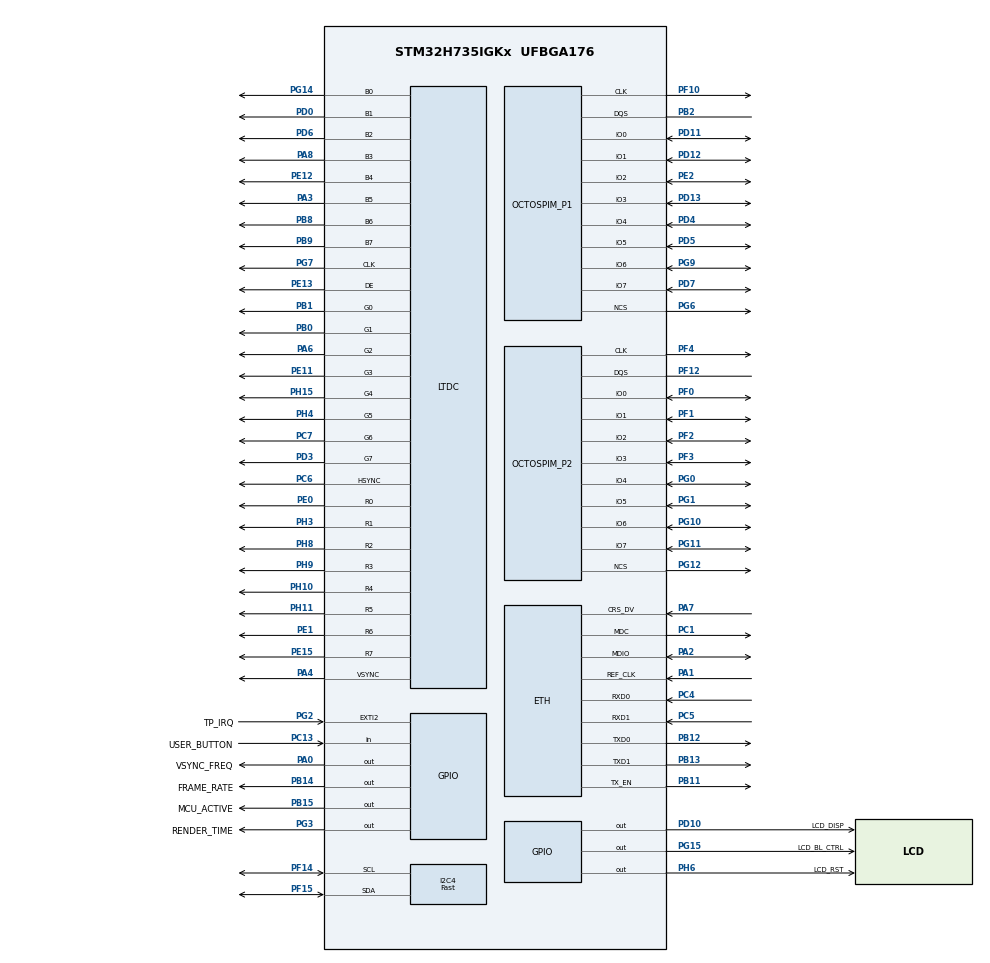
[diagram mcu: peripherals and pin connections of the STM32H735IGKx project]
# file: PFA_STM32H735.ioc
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CORTEX_M7.AccessPermission-Cortex_Memory_Protection_Unit_Region0_Settings=MPU_REGION_FULL_ACCESS
CORTEX_M7.AccessPermission-Cortex_Memory_Protection_Unit_Region2_Settings=MPU_REGION_FULL_ACCESS
CORTEX_M7.AccessPermission-Cortex_Memory_Protection_Unit_Region4_Settings=MPU_REGION_FULL_ACCESS
CORTEX_M7.BaseAddress-Cortex_Memory_Protection_Unit_Region0_Settings=0x24000000
CORTEX_M7.BaseAddress-Cortex_Memory_Protection_Unit_Region1_Settings=0x70000000
CORTEX_M7.BaseAddress-Cortex_Memory_Protection_Unit_Region2_Settings=0x70000000
CORTEX_M7.BaseAddress-Cortex_Memory_Protection_Unit_Region3_Settings=0x90000000
CORTEX_M7.BaseAddress-Cortex_Memory_Protection_Unit_Region4_Settings=0x90000000
CORTEX_M7.CPU_DCache=Enabled
CORTEX_M7.CPU_ICache=Enabled
CORTEX_M7.DisableExec-Cortex_Memory_Protection_Unit_Region0_Settings=MPU_INSTRUCTION_ACCESS_DISABLE
CORTEX_M7.DisableExec-Cortex_Memory_Protection_Unit_Region1_Settings=MPU_INSTRUCTION_ACCESS_DISABLE
CORTEX_M7.DisableExec-Cortex_Memory_Protection_Unit_Region2_Settings=MPU_INSTRUCTION_ACCESS_DISABLE
CORTEX_M7.DisableExec-Cortex_Memory_Protection_Unit_Region3_Settings=MPU_INSTRUCTION_ACCESS_DISABLE
CORTEX_M7.DisableExec-Cortex_Memory_Protection_Unit_Region4_Settings=MPU_INSTRUCTION_ACCESS_DISABLE
CORTEX_M7.Enable-Cortex_Memory_Protection_Unit_Region0_Settings=MPU_REGION_ENABLE
CORTEX_M7.Enable-Cortex_Memory_Protection_Unit_Region1_Settings=MPU_REGION_ENABLE
CORTEX_M7.Enable-Cortex_Memory_Protection_Unit_Region2_Settings=MPU_REGION_ENABLE
CORTEX_M7.Enable-Cortex_Memory_Protection_Unit_Region3_Settings=MPU_REGION_ENABLE
CORTEX_M7.Enable-Cortex_Memory_Protection_Unit_Region4_Settings=MPU_REGION_ENABLE
CORTEX_M7.IsBufferable-Cortex_Memory_Protection_Unit_Region0_Settings=MPU_ACCESS_BUFFERABLE
CORTEX_M7.IsBufferable-Cortex_Memory_Protection_Unit_Region2_Settings=MPU_ACCESS_BUFFERABLE
CORTEX_M7.IsCacheable-Cortex_Memory_Protection_Unit_Region0_Settings=MPU_ACCESS_CACHEABLE
CORTEX_M7.IsCacheable-Cortex_Memory_Protection_Unit_Region2_Settings=MPU_ACCESS_CACHEABLE
CORTEX_M7.IsCacheable-Cortex_Memory_Protection_Unit_Region4_Settings=MPU_ACCESS_CACHEABLE
CORTEX_M7.MPU_Control=MPU_PRIVILEGED_DEFAULT
CORTEX_M7.Size-Cortex_Memory_Protection_Unit_Region0_Settings=MPU_REGION_SIZE_512KB
CORTEX_M7.Size-Cortex_Memory_Protection_Unit_Region1_Settings=MPU_REGION_SIZE_512MB
CORTEX_M7.Size-Cortex_Memory_Protection_Unit_Region2_Settings=MPU_REGION_SIZE_8MB
CORTEX_M7.Size-Cortex_Memory_Protection_Unit_Region3_Settings=MPU_REGION_SIZE_512MB
CORTEX_M7.Size-Cortex_Memory_Protection_Unit_Region4_Settings=MPU_REGION_SIZE_64MB
CORTEX_M7.TypeExtField-Cortex_Memory_Protection_Unit_Region0_Settings=MPU_TEX_LEVEL1
DMA2D.ColorMode=DMA2D_OUTPUT_RGB888
DMA2D.Mode=DMA2D_R2M
ETH.MediaInterface=HAL_ETH_RMII_MODE
FREERTOS.Tasks01=defaultTask,24,2048,StartDefaultTask,Default,NULL,Dynamic,NULL,NULL;TouchGFXTask,24,2048,TouchGFX_Task,As external,NULL,Dynamic,NULL,NULL;videoTask,8,1024,videoTaskFunc,As external,NULL,Dynamic,NULL,NULL
FREERTOS.configTOTAL_HEAP_SIZE=75000
FREERTOS.configUSE_APPLICATION_TASK_TAG=1
FREERTOS.configUSE_IDLE_HOOK=1
I2C4.I2C_Speed_Mode=I2C_Fast
I2C4.Timing=0x00D049FB
LIBJPEG.RGB_ORDERING=BGR
LTDC.ActiveH=272
LTDC.ActiveW=480
LTDC.Alpha_L0=255
LTDC.FBStartAdress_L0=0x70000000
LTDC.FBStartAdress_L1=0x70000000
LTDC.HBP=13
LTDC.HFP=32
LTDC.HSync=41
LTDC.ImageHeight_L0=272
LTDC.ImageWidth_L0=480
LTDC.Layers=0
LTDC.PixelFormat_L0=LTDC_PIXEL_FORMAT_RGB888
LTDC.VSync=10
LTDC.WindowX1_L0=480
LTDC.WindowY1_L0=272
LWIP.BSP.number=1
LWIP.GATEWAY_ADDRESS=192.168.000.001
LWIP.IP_ADDRESS=192.168.000.020
LWIP.LWIP_DHCP=0
LWIP.LWIP_IPV6=1
LWIP.NETMASK_ADDRESS=255.255.255.000
LWIP.Version=v2.2.1_Cube
LWIP0.BSP.STBoard=false
LWIP0.BSP.api=BSP_COMPONENT_DRIVER
LWIP0.BSP.component=LAN8742
LWIP0.BSP.instance=LAN8742
LWIP0.BSP.name=Driver_PHY
LWIP0.BSP.semaphore=S_LAN8742
LWIP0.BSP.solution=LAN8742
Mcu.Family=STM32H7
Mcu.Name=STM32H735IGKx
Mcu.Package=UFBGA176
NVIC.DMA2D_IRQn=true\:5\:0\:true\:false\:true\:false\:true\:true\:true
NVIC.ETH_IRQn=true\:5\:0\:false\:false\:true\:true\:true\:true\:true
NVIC.EXTI2_IRQn=true\:5\:0\:false\:false\:true\:true\:true\:true\:true
NVIC.LTDC_IRQn=true\:5\:0\:true\:false\:true\:false\:true\:true\:true
NVIC.PriorityGroup=NVIC_PRIORITYGROUP_4
NVIC.TIM6_DAC_IRQn=true\:0\:0\:false\:false\:true\:false\:false\:true\:true
NVIC.TimeBase=TIM6_DAC_IRQn
NVIC.TimeBaseIP=TIM6
OCTOSPI1.ChipSelectBoundary=0
OCTOSPI1.ChipSelectHighTime=2
OCTOSPI1.ClockPrescaler=2
OCTOSPI1.FifoThreshold=4
OCTOSPI1.MemoryType=HAL_OSPI_MEMTYPE_MACRONIX
OCTOSPI2.AccessTime=6
OCTOSPI2.ChipSelectBoundary=23
OCTOSPI2.ChipSelectHighTime=4
OCTOSPI2.ClkChipSelectHighTime=0
OCTOSPI2.ClockPrescaler=2
OCTOSPI2.DelayBlockBypass=HAL_OSPI_DELAY_BLOCK_USED
OCTOSPI2.DelayHoldQuarterCycle=HAL_OSPI_DHQC_ENABLE
OCTOSPI2.DeviceSize=24
OCTOSPI2.FifoThreshold=4
OCTOSPI2.LatencyMode=HAL_OSPI_FIXED_LATENCY
OCTOSPI2.RWRecoveryTime=3
OCTOSPI2.Refresh=400
OCTOSPI2.WriteZeroLatency=HAL_OSPI_LATENCY_ON_WRITE
PA0.GPIO_Label=VSYNC_FREQ
PA0.GPIO_Speed=GPIO_SPEED_FREQ_VERY_HIGH
PA0.Signal=GPIO_Output
PA1.Mode=RMII
PA1.Signal=ETH_REF_CLK
PA2.Mode=RMII
PA2.Signal=ETH_MDIO
PA3.GPIO_Speed=GPIO_SPEED_FREQ_VERY_HIGH
PA3.Mode=RGB888
PA3.Signal=LTDC_B5
PA4.GPIO_Speed=GPIO_SPEED_FREQ_VERY_HIGH
PA4.Mode=RGB888
PA4.Signal=LTDC_VSYNC
PA6.GPIO_Speed=GPIO_SPEED_FREQ_VERY_HIGH
PA6.Mode=RGB888
PA6.Signal=LTDC_G2
PA7.Mode=RMII
PA7.Signal=ETH_CRS_DV
PA8.GPIO_Speed=GPIO_SPEED_FREQ_VERY_HIGH
PA8.Mode=RGB888
PA8.Signal=LTDC_B3
PB0.GPIO_Speed=GPIO_SPEED_FREQ_VERY_HIGH
PB0.Mode=RGB888
PB0.Signal=LTDC_G1
PB1.GPIO_Speed=GPIO_SPEED_FREQ_VERY_HIGH
PB1.Mode=RGB888
PB1.Signal=LTDC_G0
PB10.Signal=ETH_RX_ER
PB11.Mode=RMII
PB11.Signal=ETH_TX_EN
PB12.Mode=RMII
PB12.Signal=ETH_TXD0
PB13.Mode=RMII
PB13.Signal=ETH_TXD1
PB14.GPIO_Label=FRAME_RATE
PB14.GPIO_Speed=GPIO_SPEED_FREQ_VERY_HIGH
PB14.Signal=GPIO_Output
PB15.GPIO_Label=MCU_ACTIVE
PB15.GPIO_Speed=GPIO_SPEED_FREQ_VERY_HIGH
PB15.Signal=GPIO_Output
PB2.Mode=OCTOSPI1_Port1_DQS
PB2.Signal=OCTOSPIM_P1_DQS
PB8.GPIO_Speed=GPIO_SPEED_FREQ_VERY_HIGH
PB8.Mode=RGB888
PB8.Signal=LTDC_B6
PB9.GPIO_Speed=GPIO_SPEED_FREQ_VERY_HIGH
PB9.Mode=RGB888
PB9.Signal=LTDC_B7
PC1.Mode=RMII
PC1.Signal=ETH_MDC
PC13.GPIO_Label=USER_BUTTON
PC13.Signal=GPIO_Input
PC4.Mode=RMII
PC4.Signal=ETH_RXD0
PC5.Mode=RMII
PC5.Signal=ETH_RXD1
PC6.GPIO_Speed=GPIO_SPEED_FREQ_VERY_HIGH
PC6.Mode=RGB888
PC6.Signal=LTDC_HSYNC
PC7.GPIO_Speed=GPIO_SPEED_FREQ_VERY_HIGH
PC7.Mode=RGB888
PC7.Signal=LTDC_G6
PD0.GPIO_Speed=GPIO_SPEED_FREQ_VERY_HIGH
PD0.Mode=RGB888
PD0.Signal=LTDC_B1
PD10.GPIO_Label=LCD_DISP
PD10.GPIO_PuPd=GPIO_NOPULL
PD10.GPIO_Speed=GPIO_SPEED_FREQ_LOW
PD10.PinState=GPIO_PIN_RESET
PD10.Signal=GPIO_Output
PD11.Mode=OCTOSPI1_IOL_Port1L
PD11.Signal=OCTOSPIM_P1_IO0
PD12.Mode=OCTOSPI1_IOL_Port1L
PD12.Signal=OCTOSPIM_P1_IO1
PD13.Mode=OCTOSPI1_IOL_Port1L
PD13.Signal=OCTOSPIM_P1_IO3
PD3.GPIO_Speed=GPIO_SPEED_FREQ_VERY_HIGH
PD3.Mode=RGB888
PD3.Signal=LTDC_G7
PD4.Mode=OCTOSPI1_IOH_Port1H
PD4.Signal=OCTOSPIM_P1_IO4
PD5.Mode=OCTOSPI1_IOH_Port1H
PD5.Signal=OCTOSPIM_P1_IO5
PD6.GPIO_Speed=GPIO_SPEED_FREQ_VERY_HIGH
PD6.Mode=RGB888
PD6.Signal=LTDC_B2
PD7.Mode=OCTOSPI1_IOH_Port1H
PD7.Signal=OCTOSPIM_P1_IO7
PE0.GPIO_Speed=GPIO_SPEED_FREQ_VERY_HIGH
PE0.Mode=RGB888
PE0.Signal=LTDC_R0
PE1.GPIO_Speed=GPIO_SPEED_FREQ_VERY_HIGH
PE1.Mode=RGB888
PE1.Signal=LTDC_R6
PE11.GPIO_Speed=GPIO_SPEED_FREQ_VERY_HIGH
PE11.Mode=RGB888
PE11.Signal=LTDC_G3
PE12.GPIO_Speed=GPIO_SPEED_FREQ_VERY_HIGH
PE12.Mode=RGB888
PE12.Signal=LTDC_B4
PE13.GPIO_Speed=GPIO_SPEED_FREQ_VERY_HIGH
PE13.Mode=RGB888
PE13.Signal=LTDC_DE
PE15.GPIO_Speed=GPIO_SPEED_FREQ_VERY_HIGH
PE15.Mode=RGB888
PE15.Signal=LTDC_R7
PE2.Mode=OCTOSPI1_IOL_Port1L
PE2.Signal=OCTOSPIM_P1_IO2
PF0.Mode=OCTOSPI2_IOL_Port2L
PF0.Signal=OCTOSPIM_P2_IO0
PF1.Mode=OCTOSPI2_IOL_Port2L
PF1.Signal=OCTOSPIM_P2_IO1
PF10.Mode=O1_P1_CLK
PF10.Signal=OCTOSPIM_P1_CLK
PF12.Mode=OCTOSPI2_Port2_DQS
PF12.Signal=OCTOSPIM_P2_DQS
PF14.Mode=I2C
PF14.Signal=I2C4_SCL
PF15.Mode=I2C
PF15.Signal=I2C4_SDA
PF2.Mode=OCTOSPI2_IOL_Port2L
PF2.Signal=OCTOSPIM_P2_IO2
PF3.Mode=OCTOSPI2_IOL_Port2L
PF3.Signal=OCTOSPIM_P2_IO3
PF4.Mode=O2_P2_CLK
PF4.Signal=OCTOSPIM_P2_CLK
PG0.Mode=OCTOSPI2_IOH_Port2H
PG0.Signal=OCTOSPIM_P2_IO4
PG1.Mode=OCTOSPI2_IOH_Port2H
PG1.Signal=OCTOSPIM_P2_IO5
PG10.Mode=OCTOSPI2_IOH_Port2H
PG10.Signal=OCTOSPIM_P2_IO6
PG11.Mode=OCTOSPI2_IOH_Port2H
PG11.Signal=OCTOSPIM_P2_IO7
PG12.Mode=OCTOSPI2_Port2_NCS
PG12.Signal=OCTOSPIM_P2_NCS
PG14.GPIO_Speed=GPIO_SPEED_FREQ_VERY_HIGH
PG14.Mode=RGB888
PG14.Signal=LTDC_B0
PG15.GPIO_Label=LCD_BL_CTRL
PG15.Signal=GPIO_Output
PG2.GPIO_Label=TP_IRQ
PG2.GPIO_ModeDefaultEXTI=GPIO_MODE_IT_FALLING
PG2.GPIO_PuPd=GPIO_PULLDOWN
PG2.Signal=GPXTI2
PG3.GPIO_Label=RENDER_TIME
PG3.GPIO_Speed=GPIO_SPEED_FREQ_VERY_HIGH
PG3.Signal=GPIO_Output
PG6.Mode=OCTOSPI1_Port1_NCS
PG6.Signal=OCTOSPIM_P1_NCS
PG7.GPIO_Speed=GPIO_SPEED_FREQ_VERY_HIGH
PG7.Mode=RGB888
PG7.Signal=LTDC_CLK
PG9.Mode=OCTOSPI1_IOH_Port1H
PG9.Signal=OCTOSPIM_P1_IO6
PH0-OSC_IN.Mode=HSE-External-Oscillator
PH0-OSC_IN.Signal=RCC_OSC_IN
PH1-OSC_OUT.Mode=HSE-External-Oscillator
PH1-OSC_OUT.Signal=RCC_OSC_OUT
PH10.GPIO_Speed=GPIO_SPEED_FREQ_VERY_HIGH
PH10.Mode=RGB888
PH10.Signal=LTDC_R4
PH11.GPIO_Speed=GPIO_SPEED_FREQ_VERY_HIGH
PH11.Mode=RGB888
PH11.Signal=LTDC_R5
PH15.GPIO_Speed=GPIO_SPEED_FREQ_VERY_HIGH
PH15.Mode=RGB888
PH15.Signal=LTDC_G4
PH3.GPIO_Speed=GPIO_SPEED_FREQ_VERY_HIGH
PH3.Mode=RGB888
PH3.Signal=LTDC_R1
PH4.GPIO_Speed=GPIO_SPEED_FREQ_VERY_HIGH
PH4.Mode=RGB888
PH4.Signal=LTDC_G5
PH6.GPIO_Label=LCD_RST
PH6.Signal=GPIO_Output
PH8.GPIO_Speed=GPIO_SPEED_FREQ_VERY_HIGH
PH8.Mode=RGB888
PH8.Signal=LTDC_R2
PH9.GPIO_Speed=GPIO_SPEED_FREQ_VERY_HIGH
PH9.Mode=RGB888
PH9.Signal=LTDC_R3
ProjectManager.HeapSize=0x1000
ProjectManager.StackSize=0x1000
ProjectManager.TargetToolchain=STM32CubeIDE
RCC.ADCFreq_Value=200000000
RCC.APB1Freq_Value=137500000
RCC.APB2Freq_Value=137500000
RCC.APB3Freq_Value=137500000
RCC.APB4Freq_Value=137500000
RCC.CortexFreq_Value=550000000
RCC.D1PPRE=RCC_APB3_DIV2
RCC.D2PPRE1=RCC_APB1_DIV2
RCC.D2PPRE2=RCC_APB2_DIV2
RCC.D3PPRE=RCC_APB4_DIV2
RCC.DIVM1=2
RCC.DIVM2=5
RCC.DIVM3=25
RCC.DIVN1=44
RCC.DIVN2=80
RCC.DIVN3=288
RCC.DIVP1=1
RCC.DIVR3=30
RCC.HCLKFreq_Value=275000000
RCC.HPRE=RCC_HCLK_DIV2
RCC.PLL2FRACN=0
RCC.PLL3FRACN=0
RCC.PLLFRACN=0
RCC.PLLSourceVirtual=RCC_PLLSOURCE_HSE
RCC.QSPICLockSelection=RCC_OSPICLKSOURCE_PLL2
RCC.SYSCLKFreq_VALUE=550000000
RCC.SYSCLKSource=RCC_SYSCLKSOURCE_PLLCLK
RCC.SupplySource=PWR_DIRECT_SMPS_SUPPLY
RCC.USBFreq_Value=275000000
STMicroelectronics.X-CUBE-TOUCHGFX.4.26.1.ApplicationCcGraphicsJjApplication=TouchGFXOoGenerator
STMicroelectronics.X-CUBE-TOUCHGFX.4.26.1.tgfx_address1=0x70000000
STMicroelectronics.X-CUBE-TOUCHGFX.4.26.1.tgfx_address2=0x70060000
STMicroelectronics.X-CUBE-TOUCHGFX.4.26.1.tgfx_buffering_strategy=Double
STMicroelectronics.X-CUBE-TOUCHGFX.4.26.1.tgfx_display_interface=disp_ltdc
STMicroelectronics.X-CUBE-TOUCHGFX.4.26.1.tgfx_hardware_accelerator=dma_2d
STMicroelectronics.X-CUBE-TOUCHGFX.4.26.1.tgfx_location=Allocate
STMicroelectronics.X-CUBE-TOUCHGFX.4.26.1.tgfx_vector_fonts=Enabled
STMicroelectronics.X-CUBE-TOUCHGFX.4.26.1.tgfx_vector_rendering=Software
STMicroelectronics.X-CUBE-TOUCHGFX.4.26.1.tgfx_video=Software
STMicroelectronics.X-CUBE-TOUCHGFX.4.26.1.tgfx_video_buffer_format=RGB888\:3
STMicroelectronics.X-CUBE-TOUCHGFX.4.26.1.tgfx_video_height=272
STMicroelectronics.X-CUBE-TOUCHGFX.4.26.1.tgfx_video_strategy=1
STMicroelectronics.X-CUBE-TOUCHGFX.4.26.1.tgfx_video_width=480
STMicroelectronics.X-CUBE-TOUCHGFX.4.26.1.tgfx_vsync=vsync_ltdc
VP_CRC_VS_CRC.Mode=CRC_Activate
VP_DMA2D_VS_DMA2D.Mode=DMA2D_Activate
VP_FREERTOS_VS_CMSIS_V2.Mode=CMSIS_V2
VP_LIBJPEG_VS_JPEGLIB.Mode=Enabled
VP_LWIP_VS_Enabled.Mode=Enabled
VP_MEMORYMAP_VS_MEMORYMAP.Mode=CurAppReg
VP_OCTOSPI1_VS_octo.Mode=octo_mode
VP_OCTOSPI2_VS_octo.Mode=hyperbus_mode
VP_STMicroelectronics.X-CUBE-TOUCHGFX_VS_GraphicsJjApplication_4.26.1.Mode=GraphicsJjApplication
VP_SYS_VS_tim6.Mode=TIM6
board=custom

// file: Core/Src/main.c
/* USER CODE BEGIN Header */
/**
  ******************************************************************************
  * @file           : main.c
  * @brief          : Main program body
  ******************************************************************************
  * @attention
  *
  * <h2><center>&copy; Copyright (c) 2020 STMicroelectronics.
  * All rights reserved.</center></h2>
  *
  * This software component is licensed by ST under Ultimate Liberty license
  * SLA0044, the "License"; You may not use this file except in compliance with
  * the License. You may obtain a copy of the License at:
  *                             www.st.com/SLA0044
  *
  ******************************************************************************
  */
/* USER CODE END Header */
#include "main.h"
#include "FreeRTOS.h"
#include "cmsis_os2.h"
#include "libjpeg.h"
#include "lwip.h"
#include "app_touchgfx.h"

/* USER CODE BEGIN Includes */
#include "task.h"
#include "stm32h735g_discovery_ospi.h"
#include "stm32h7xx_hal_ospi.h"
/* USER CODE END Includes */

CRC_HandleTypeDef hcrc;

DMA2D_HandleTypeDef hdma2d;

I2C_HandleTypeDef hi2c4;

LTDC_HandleTypeDef hltdc;

OSPI_HandleTypeDef hospi1;
OSPI_HandleTypeDef hospi2;

/* Definitions for defaultTask */
osThreadId_t defaultTaskHandle;
const osThreadAttr_t defaultTask_attributes = {
  .name = "defaultTask",
  .stack_size = 2048 * 4,
  .priority = (osPriority_t) osPriorityNormal,
};
/* Definitions for TouchGFXTask */
osThreadId_t TouchGFXTaskHandle;
const osThreadAttr_t TouchGFXTask_attributes = {
  .name = "TouchGFXTask",
  .stack_size = 2048 * 4,
  .priority = (osPriority_t) osPriorityNormal,
};
/* Definitions for videoTask */
osThreadId_t videoTaskHandle;
const osThreadAttr_t videoTask_attributes = {
  .name = "videoTask",
  .stack_size = 1024 * 4,
  .priority = (osPriority_t) osPriorityLow,
};

void SystemClock_Config(void);
void PeriphCommonClock_Config(void);
static void MPU_Config(void);
static void MX_GPIO_Init(void);
static void MX_CRC_Init(void);
static void MX_DMA2D_Init(void);
static void MX_LTDC_Init(void);
static void MX_OCTOSPI1_Init(void);
static void MX_OCTOSPI2_Init(void);
static void MX_I2C4_Init(void);
void StartDefaultTask(void *argument);
extern void TouchGFX_Task(void *argument);
extern void videoTaskFunc(void *argument);

int main(void)
{

  /* MPU Configuration--------------------------------------------------------*/
  MPU_Config();

  /* Enable the CPU Cache */

  /* Enable I-Cache---------------------------------------------------------*/
  SCB_EnableICache();

  /* Enable D-Cache---------------------------------------------------------*/
  SCB_EnableDCache();

  /* MCU Configuration--------------------------------------------------------*/

  /* Reset of all peripherals, Initializes the Flash interface and the Systick. */
  HAL_Init();

  /* USER CODE BEGIN Init */

  {
    MPU_Region_InitTypeDef MPU_InitStruct = {0};
    HAL_MPU_Disable();
    MPU_InitStruct.Enable = MPU_REGION_ENABLE;
    MPU_InitStruct.Number = MPU_REGION_NUMBER0;
    MPU_InitStruct.BaseAddress = 0x24000000;
    MPU_InitStruct.Size = MPU_REGION_SIZE_512KB;
    MPU_InitStruct.SubRegionDisable = 0x0;
    MPU_InitStruct.TypeExtField = MPU_TEX_LEVEL1;
    MPU_InitStruct.AccessPermission = MPU_REGION_FULL_ACCESS;
    MPU_InitStruct.DisableExec = MPU_INSTRUCTION_ACCESS_DISABLE;
    MPU_InitStruct.IsShareable = MPU_ACCESS_NOT_SHAREABLE;
    MPU_InitStruct.IsCacheable = MPU_ACCESS_CACHEABLE;
    MPU_InitStruct.IsBufferable = MPU_ACCESS_BUFFERABLE;
    HAL_MPU_ConfigRegion(&MPU_InitStruct);

    /* Ethernet DMA Descriptors at 0x30000000 (Non-cacheable) */
    MPU_InitStruct.Number = MPU_REGION_NUMBER5;
    MPU_InitStruct.BaseAddress = 0x30000000;
    MPU_InitStruct.Size = MPU_REGION_SIZE_256B;
    MPU_InitStruct.TypeExtField = MPU_TEX_LEVEL0;
    MPU_InitStruct.IsShareable = MPU_ACCESS_SHAREABLE;
    MPU_InitStruct.IsCacheable = MPU_ACCESS_NOT_CACHEABLE;
    MPU_InitStruct.IsBufferable = MPU_ACCESS_NOT_BUFFERABLE;
    HAL_MPU_ConfigRegion(&MPU_InitStruct);

    HAL_MPU_Enable(MPU_PRIVILEGED_DEFAULT);
  }

  /* USER CODE END Init */

  /* Configure the system clock */
  SystemClock_Config();

  /* Configure the peripherals common clocks */
  PeriphCommonClock_Config();

  /* Initialize all configured peripherals */
  MX_GPIO_Init();
  MX_CRC_Init();
  MX_DMA2D_Init();
  MX_LTDC_Init();
  MX_OCTOSPI1_Init();
  MX_OCTOSPI2_Init();
  MX_LIBJPEG_Init();
  MX_I2C4_Init();
  MX_TouchGFX_Init();
  /* Call PreOsInit function */
  MX_TouchGFX_PreOSInit();

  /* Init scheduler */
  osKernelInitialize();

  /* Create the thread(s) */
  /* creation of defaultTask */
  defaultTaskHandle = osThreadNew(StartDefaultTask, NULL, &defaultTask_attributes);

  /* creation of TouchGFXTask */
  TouchGFXTaskHandle = osThreadNew(TouchGFX_Task, NULL, &TouchGFXTask_attributes);

  /* creation of videoTask */
  videoTaskHandle = osThreadNew(videoTaskFunc, NULL, &videoTask_attributes);

  /* Start scheduler */
  osKernelStart();

  /* We should never get here as control is now taken by the scheduler */

  /* Infinite loop */
  while (1)
  {

  }
}

void SystemClock_Config(void)
{
  RCC_OscInitTypeDef RCC_OscInitStruct = {0};
  RCC_ClkInitTypeDef RCC_ClkInitStruct = {0};

  /** Supply configuration update enable
  */
  HAL_PWREx_ConfigSupply(PWR_DIRECT_SMPS_SUPPLY);

  /** Configure the main internal regulator output voltage
  */
  __HAL_PWR_VOLTAGESCALING_CONFIG(PWR_REGULATOR_VOLTAGE_SCALE0);

  while(!__HAL_PWR_GET_FLAG(PWR_FLAG_VOSRDY)) {}

  /** Initializes the RCC Oscillators according to the specified parameters
  * in the RCC_OscInitTypeDef structure.
  */
  RCC_OscInitStruct.OscillatorType = RCC_OSCILLATORTYPE_HSE;
  RCC_OscInitStruct.HSEState = RCC_HSE_ON;
  RCC_OscInitStruct.PLL.PLLState = RCC_PLL_ON;
  RCC_OscInitStruct.PLL.PLLSource = RCC_PLLSOURCE_HSE;
  RCC_OscInitStruct.PLL.PLLM = 2;
  RCC_OscInitStruct.PLL.PLLN = 44;
  RCC_OscInitStruct.PLL.PLLP = 1;
  RCC_OscInitStruct.PLL.PLLQ = 2;
  RCC_OscInitStruct.PLL.PLLR = 2;
  RCC_OscInitStruct.PLL.PLLRGE = RCC_PLL1VCIRANGE_3;
  RCC_OscInitStruct.PLL.PLLVCOSEL = RCC_PLL1VCOWIDE;
  RCC_OscInitStruct.PLL.PLLFRACN = 0;
  if (HAL_RCC_OscConfig(&RCC_OscInitStruct) != HAL_OK)
  {
    Error_Handler();
  }

  /** Initializes the CPU, AHB and APB buses clocks
  */
  RCC_ClkInitStruct.ClockType = RCC_CLOCKTYPE_HCLK|RCC_CLOCKTYPE_SYSCLK
                              |RCC_CLOCKTYPE_PCLK1|RCC_CLOCKTYPE_PCLK2
                              |RCC_CLOCKTYPE_D3PCLK1|RCC_CLOCKTYPE_D1PCLK1;
  RCC_ClkInitStruct.SYSCLKSource = RCC_SYSCLKSOURCE_PLLCLK;
  RCC_ClkInitStruct.SYSCLKDivider = RCC_SYSCLK_DIV1;
  RCC_ClkInitStruct.AHBCLKDivider = RCC_HCLK_DIV2;
  RCC_ClkInitStruct.APB3CLKDivider = RCC_APB3_DIV2;
  RCC_ClkInitStruct.APB1CLKDivider = RCC_APB1_DIV2;
  RCC_ClkInitStruct.APB2CLKDivider = RCC_APB2_DIV2;
  RCC_ClkInitStruct.APB4CLKDivider = RCC_APB4_DIV2;

  if (HAL_RCC_ClockConfig(&RCC_ClkInitStruct, FLASH_LATENCY_3) != HAL_OK)
  {
    Error_Handler();
  }
}

void PeriphCommonClock_Config(void)
{
  RCC_PeriphCLKInitTypeDef PeriphClkInitStruct = {0};

  /** Initializes the peripherals clock
  */
  PeriphClkInitStruct.PeriphClockSelection = RCC_PERIPHCLK_OSPI;
  PeriphClkInitStruct.PLL2.PLL2M = 5;
  PeriphClkInitStruct.PLL2.PLL2N = 80;
  PeriphClkInitStruct.PLL2.PLL2P = 2;
  PeriphClkInitStruct.PLL2.PLL2Q = 2;
  PeriphClkInitStruct.PLL2.PLL2R = 2;
  PeriphClkInitStruct.PLL2.PLL2RGE = RCC_PLL2VCIRANGE_2;
  PeriphClkInitStruct.PLL2.PLL2VCOSEL = RCC_PLL2VCOWIDE;
  PeriphClkInitStruct.PLL2.PLL2FRACN = 0;
  PeriphClkInitStruct.OspiClockSelection = RCC_OSPICLKSOURCE_PLL2;
  if (HAL_RCCEx_PeriphCLKConfig(&PeriphClkInitStruct) != HAL_OK)
  {
    Error_Handler();
  }
}

static void MX_CRC_Init(void)
{

  hcrc.Instance = CRC;
  hcrc.Init.DefaultPolynomialUse = DEFAULT_POLYNOMIAL_ENABLE;
  hcrc.Init.DefaultInitValueUse = DEFAULT_INIT_VALUE_ENABLE;
  hcrc.Init.InputDataInversionMode = CRC_INPUTDATA_INVERSION_NONE;
  hcrc.Init.OutputDataInversionMode = CRC_OUTPUTDATA_INVERSION_DISABLE;
  hcrc.InputDataFormat = CRC_INPUTDATA_FORMAT_BYTES;
  if (HAL_CRC_Init(&hcrc) != HAL_OK)
  {
    Error_Handler();
  }

}

static void MX_DMA2D_Init(void)
{

  hdma2d.Instance = DMA2D;
  hdma2d.Init.Mode = DMA2D_R2M;
  hdma2d.Init.ColorMode = DMA2D_OUTPUT_RGB888;
  hdma2d.Init.OutputOffset = 0;
  if (HAL_DMA2D_Init(&hdma2d) != HAL_OK)
  {
    Error_Handler();
  }

}

static void MX_I2C4_Init(void)
{

  hi2c4.Instance = I2C4;
  hi2c4.Init.Timing = 0x00D049FB;
  hi2c4.Init.OwnAddress1 = 0;
  hi2c4.Init.AddressingMode = I2C_ADDRESSINGMODE_7BIT;
  hi2c4.Init.DualAddressMode = I2C_DUALADDRESS_DISABLE;
  hi2c4.Init.OwnAddress2 = 0;
  hi2c4.Init.OwnAddress2Masks = I2C_OA2_NOMASK;
  hi2c4.Init.GeneralCallMode = I2C_GENERALCALL_DISABLE;
  hi2c4.Init.NoStretchMode = I2C_NOSTRETCH_DISABLE;
  if (HAL_I2C_Init(&hi2c4) != HAL_OK)
  {
    Error_Handler();
  }

  /** Configure Analogue filter
  */
  if (HAL_I2CEx_ConfigAnalogFilter(&hi2c4, I2C_ANALOGFILTER_ENABLE) != HAL_OK)
  {
    Error_Handler();
  }

  /** Configure Digital filter
  */
  if (HAL_I2CEx_ConfigDigitalFilter(&hi2c4, 0) != HAL_OK)
  {
    Error_Handler();
  }

}

static void MX_LTDC_Init(void)
{

  LTDC_LayerCfgTypeDef pLayerCfg = {0};

  hltdc.Instance = LTDC;
  hltdc.Init.HSPolarity = LTDC_HSPOLARITY_AL;
  hltdc.Init.VSPolarity = LTDC_VSPOLARITY_AL;
  hltdc.Init.DEPolarity = LTDC_DEPOLARITY_AL;
  hltdc.Init.PCPolarity = LTDC_PCPOLARITY_IPC;
  hltdc.Init.HorizontalSync = 40;
  hltdc.Init.VerticalSync = 9;
  hltdc.Init.AccumulatedHBP = 53;
  hltdc.Init.AccumulatedVBP = 11;
  hltdc.Init.AccumulatedActiveW = 533;
  hltdc.Init.AccumulatedActiveH = 283;
  hltdc.Init.TotalWidth = 565;
  hltdc.Init.TotalHeigh = 285;
  hltdc.Init.Backcolor.Blue = 0;
  hltdc.Init.Backcolor.Green = 0;
  hltdc.Init.Backcolor.Red = 0;
  if (HAL_LTDC_Init(&hltdc) != HAL_OK)
  {
    Error_Handler();
  }
  pLayerCfg.WindowX0 = 0;
  pLayerCfg.WindowX1 = 480;
  pLayerCfg.WindowY0 = 0;
  pLayerCfg.WindowY1 = 272;
  pLayerCfg.PixelFormat = LTDC_PIXEL_FORMAT_RGB888;
  pLayerCfg.Alpha = 255;
  pLayerCfg.Alpha0 = 0;
  pLayerCfg.BlendingFactor1 = LTDC_BLENDING_FACTOR1_CA;
  pLayerCfg.BlendingFactor2 = LTDC_BLENDING_FACTOR2_CA;
  pLayerCfg.FBStartAdress = 0x70000000;
  pLayerCfg.ImageWidth = 480;
  pLayerCfg.ImageHeight = 272;
  pLayerCfg.Backcolor.Blue = 0;
  pLayerCfg.Backcolor.Green = 0;
  pLayerCfg.Backcolor.Red = 0;
  if (HAL_LTDC_ConfigLayer(&hltdc, &pLayerCfg, 0) != HAL_OK)
  {
    Error_Handler();
  }

}

static void MX_OCTOSPI1_Init(void)
{

  /* USER CODE BEGIN OCTOSPI1_Init 0 */
  BSP_OSPI_NOR_Init_t ospi_nor_int;
  /* USER CODE END OCTOSPI1_Init 0 */

  OSPIM_CfgTypeDef sOspiManagerCfg = {0};

  /* OCTOSPI1 parameter configuration*/
  hospi1.Instance = OCTOSPI1;
  hospi1.Init.FifoThreshold = 4;
  hospi1.Init.DualQuad = HAL_OSPI_DUALQUAD_DISABLE;
  hospi1.Init.MemoryType = HAL_OSPI_MEMTYPE_MACRONIX;
  hospi1.Init.DeviceSize = 32;
  hospi1.Init.ChipSelectHighTime = 2;
  hospi1.Init.FreeRunningClock = HAL_OSPI_FREERUNCLK_DISABLE;
  hospi1.Init.ClockMode = HAL_OSPI_CLOCK_MODE_0;
  hospi1.Init.WrapSize = HAL_OSPI_WRAP_NOT_SUPPORTED;
  hospi1.Init.ClockPrescaler = 2;
  hospi1.Init.SampleShifting = HAL_OSPI_SAMPLE_SHIFTING_NONE;
  hospi1.Init.DelayHoldQuarterCycle = HAL_OSPI_DHQC_DISABLE;
  hospi1.Init.ChipSelectBoundary = 0;
  hospi1.Init.DelayBlockBypass = HAL_OSPI_DELAY_BLOCK_BYPASSED;
  hospi1.Init.MaxTran = 0;
  hospi1.Init.Refresh = 0;
  if (HAL_OSPI_Init(&hospi1) != HAL_OK)
  {
    Error_Handler();
  }
  sOspiManagerCfg.ClkPort = 1;
  sOspiManagerCfg.DQSPort = 1;
  sOspiManagerCfg.NCSPort = 1;
  sOspiManagerCfg.IOLowPort = HAL_OSPIM_IOPORT_1_LOW;
  sOspiManagerCfg.IOHighPort = HAL_OSPIM_IOPORT_1_HIGH;
  if (HAL_OSPIM_Config(&hospi1, &sOspiManagerCfg, HAL_OSPI_TIMEOUT_DEFAULT_VALUE) != HAL_OK)
  {
    Error_Handler();
  }
  /* USER CODE BEGIN OCTOSPI1_Init 2 */
  HAL_OSPI_DeInit(&hospi1);
  ospi_nor_int.InterfaceMode = BSP_OSPI_NOR_OPI_MODE;
  ospi_nor_int.TransferRate  = BSP_OSPI_NOR_DTR_TRANSFER;
  BSP_OSPI_NOR_DeInit(0);
  if(BSP_OSPI_NOR_Init(0, &ospi_nor_int) != BSP_ERROR_NONE)
  {
    Error_Handler();
  }
  if(BSP_OSPI_NOR_EnableMemoryMappedMode(0) != BSP_ERROR_NONE)
  {
    Error_Handler();
  }
  /* USER CODE END OCTOSPI1_Init 2 */

}

static void MX_OCTOSPI2_Init(void)
{

  OSPIM_CfgTypeDef sOspiManagerCfg = {0};
  OSPI_HyperbusCfgTypeDef sHyperBusCfg = {0};

  /* USER CODE BEGIN OCTOSPI2_Init 1 */
  OSPI_HyperbusCmdTypeDef sCommand = {0};
  OSPI_MemoryMappedTypeDef sMemMappedCfg = {0};
  /* USER CODE END OCTOSPI2_Init 1 */
  /* OCTOSPI2 parameter configuration*/
  hospi2.Instance = OCTOSPI2;
  hospi2.Init.FifoThreshold = 4;
  hospi2.Init.DualQuad = HAL_OSPI_DUALQUAD_DISABLE;
  hospi2.Init.MemoryType = HAL_OSPI_MEMTYPE_HYPERBUS;
  hospi2.Init.DeviceSize = 24;
  hospi2.Init.ChipSelectHighTime = 4;
  hospi2.Init.FreeRunningClock = HAL_OSPI_FREERUNCLK_DISABLE;
  hospi2.Init.ClockMode = HAL_OSPI_CLOCK_MODE_0;
  hospi2.Init.WrapSize = HAL_OSPI_WRAP_NOT_SUPPORTED;
  hospi2.Init.ClockPrescaler = 2;
  hospi2.Init.SampleShifting = HAL_OSPI_SAMPLE_SHIFTING_NONE;
  hospi2.Init.DelayHoldQuarterCycle = HAL_OSPI_DHQC_ENABLE;
  hospi2.Init.ChipSelectBoundary = 23;
  hospi2.Init.DelayBlockBypass = HAL_OSPI_DELAY_BLOCK_USED;
  hospi2.Init.MaxTran = 0;
  hospi2.Init.Refresh = 400;
  if (HAL_OSPI_Init(&hospi2) != HAL_OK)
  {
    Error_Handler();
  }
  sOspiManagerCfg.ClkPort = 2;
  sOspiManagerCfg.DQSPort = 2;
  sOspiManagerCfg.NCSPort = 2;
  sOspiManagerCfg.IOLowPort = HAL_OSPIM_IOPORT_2_LOW;
  sOspiManagerCfg.IOHighPort = HAL_OSPIM_IOPORT_2_HIGH;
  if (HAL_OSPIM_Config(&hospi2, &sOspiManagerCfg, HAL_OSPI_TIMEOUT_DEFAULT_VALUE) != HAL_OK)
  {
    Error_Handler();
  }
  sHyperBusCfg.RWRecoveryTime = 3;
  sHyperBusCfg.AccessTime = 6;
  sHyperBusCfg.WriteZeroLatency = HAL_OSPI_LATENCY_ON_WRITE;
  sHyperBusCfg.LatencyMode = HAL_OSPI_FIXED_LATENCY;
  if (HAL_OSPI_HyperbusCfg(&hospi2, &sHyperBusCfg, HAL_OSPI_TIMEOUT_DEFAULT_VALUE) != HAL_OK)
  {
    Error_Handler();
  }
  /* USER CODE BEGIN OCTOSPI2_Init 2 */
  sCommand.AddressSpace = HAL_OSPI_MEMORY_ADDRESS_SPACE;
  sCommand.AddressSize  = HAL_OSPI_ADDRESS_32_BITS;
  sCommand.DQSMode      = HAL_OSPI_DQS_ENABLE;
  sCommand.Address      = 0;
  sCommand.NbData       = 1;

  if (HAL_OSPI_HyperbusCmd(&hospi2, &sCommand, HAL_OSPI_TIMEOUT_DEFAULT_VALUE) != HAL_OK)
  {
    Error_Handler();
  }

  sMemMappedCfg.TimeOutActivation = HAL_OSPI_TIMEOUT_COUNTER_DISABLE;

  if (HAL_OSPI_MemoryMapped(&hospi2, &sMemMappedCfg) != HAL_OK)
  {
    Error_Handler();
  }

  /* USER CODE END OCTOSPI2_Init 2 */

}

static void MX_GPIO_Init(void)
{
  GPIO_InitTypeDef GPIO_InitStruct = {0};

  /* GPIO Ports Clock Enable */
  __HAL_RCC_GPIOB_CLK_ENABLE();
  __HAL_RCC_GPIOG_CLK_ENABLE();
  __HAL_RCC_GPIOD_CLK_ENABLE();
  __HAL_RCC_GPIOE_CLK_ENABLE();
  __HAL_RCC_GPIOA_CLK_ENABLE();
  __HAL_RCC_GPIOC_CLK_ENABLE();
  __HAL_RCC_GPIOH_CLK_ENABLE();
  __HAL_RCC_GPIOF_CLK_ENABLE();

  /*Configure GPIO pin Output Level */
  HAL_GPIO_WritePin(GPIOG, LCD_BL_CTRL_Pin|RENDER_TIME_Pin, GPIO_PIN_RESET);

  /*Configure GPIO pin Output Level */
  HAL_GPIO_WritePin(GPIOB, MCU_ACTIVE_Pin|FRAME_RATE_Pin, GPIO_PIN_RESET);

  /*Configure GPIO pin Output Level */
  HAL_GPIO_WritePin(LCD_DISP_GPIO_Port, LCD_DISP_Pin, GPIO_PIN_RESET);

  /*Configure GPIO pin Output Level */
  HAL_GPIO_WritePin(VSYNC_FREQ_GPIO_Port, VSYNC_FREQ_Pin, GPIO_PIN_RESET);

  /*Configure GPIO pin Output Level */
  HAL_GPIO_WritePin(LCD_RST_GPIO_Port, LCD_RST_Pin, GPIO_PIN_RESET);

  /*Configure GPIO pin : USER_BUTTON_Pin */
  GPIO_InitStruct.Pin = USER_BUTTON_Pin;
  GPIO_InitStruct.Mode = GPIO_MODE_INPUT;
  GPIO_InitStruct.Pull = GPIO_NOPULL;
  HAL_GPIO_Init(USER_BUTTON_GPIO_Port, &GPIO_InitStruct);

  /*Configure GPIO pin : LCD_BL_CTRL_Pin */
  GPIO_InitStruct.Pin = LCD_BL_CTRL_Pin;
  GPIO_InitStruct.Mode = GPIO_MODE_OUTPUT_PP;
  GPIO_InitStruct.Pull = GPIO_NOPULL;
  GPIO_InitStruct.Speed = GPIO_SPEED_FREQ_LOW;
  HAL_GPIO_Init(LCD_BL_CTRL_GPIO_Port, &GPIO_InitStruct);

  /*Configure GPIO pin : TP_IRQ_Pin */
  GPIO_InitStruct.Pin = TP_IRQ_Pin;
  GPIO_InitStruct.Mode = GPIO_MODE_IT_FALLING;
  GPIO_InitStruct.Pull = GPIO_PULLDOWN;
  HAL_GPIO_Init(TP_IRQ_GPIO_Port, &GPIO_InitStruct);

  /*Configure GPIO pin : RENDER_TIME_Pin */
  GPIO_InitStruct.Pin = RENDER_TIME_Pin;
  GPIO_InitStruct.Mode = GPIO_MODE_OUTPUT_PP;
  GPIO_InitStruct.Pull = GPIO_NOPULL;
  GPIO_InitStruct.Speed = GPIO_SPEED_FREQ_VERY_HIGH;
  HAL_GPIO_Init(RENDER_TIME_GPIO_Port, &GPIO_InitStruct);

  /*Configure GPIO pins : MCU_ACTIVE_Pin FRAME_RATE_Pin */
  GPIO_InitStruct.Pin = MCU_ACTIVE_Pin|FRAME_RATE_Pin;
  GPIO_InitStruct.Mode = GPIO_MODE_OUTPUT_PP;
  GPIO_InitStruct.Pull = GPIO_NOPULL;
  GPIO_InitStruct.Speed = GPIO_SPEED_FREQ_VERY_HIGH;
  HAL_GPIO_Init(GPIOB, &GPIO_InitStruct);

  /*Configure GPIO pin : LCD_DISP_Pin */
  GPIO_InitStruct.Pin = LCD_DISP_Pin;
  GPIO_InitStruct.Mode = GPIO_MODE_OUTPUT_PP;
  GPIO_InitStruct.Pull = GPIO_NOPULL;
  GPIO_InitStruct.Speed = GPIO_SPEED_FREQ_LOW;
  HAL_GPIO_Init(LCD_DISP_GPIO_Port, &GPIO_InitStruct);

  /*Configure GPIO pin : VSYNC_FREQ_Pin */
  GPIO_InitStruct.Pin = VSYNC_FREQ_Pin;
  GPIO_InitStruct.Mode = GPIO_MODE_OUTPUT_PP;
  GPIO_InitStruct.Pull = GPIO_NOPULL;
  GPIO_InitStruct.Speed = GPIO_SPEED_FREQ_VERY_HIGH;
  HAL_GPIO_Init(VSYNC_FREQ_GPIO_Port, &GPIO_InitStruct);

  /*Configure GPIO pin : LCD_RST_Pin */
  GPIO_InitStruct.Pin = LCD_RST_Pin;
  GPIO_InitStruct.Mode = GPIO_MODE_OUTPUT_PP;
  GPIO_InitStruct.Pull = GPIO_NOPULL;
  GPIO_InitStruct.Speed = GPIO_SPEED_FREQ_LOW;
  HAL_GPIO_Init(LCD_RST_GPIO_Port, &GPIO_InitStruct);

  /*AnalogSwitch Config */
  HAL_SYSCFG_AnalogSwitchConfig(SYSCFG_SWITCH_PA0, SYSCFG_SWITCH_PA0_CLOSE);

  /* EXTI interrupt init*/
  HAL_NVIC_SetPriority(TP_IRQ_EXTI_IRQn, 5, 0);
  HAL_NVIC_EnableIRQ(TP_IRQ_EXTI_IRQn);

  /* USER CODE BEGIN MX_GPIO_Init_2 */
  HAL_Delay(1);
  HAL_GPIO_WritePin(LCD_RST_GPIO_Port, LCD_RST_Pin, GPIO_PIN_SET);
  /* USER CODE END MX_GPIO_Init_2 */
}

/* USER CODE BEGIN 4 */

void vApplicationStackOverflowHook(TaskHandle_t xTask, char *pcTaskName)
{
  __disable_irq();
  while (1)
  {
    /* Point d'arrêt ici : xTask et pcTaskName indiquent la tâche en cause */
  }
}

/* USER CODE END 4 */

void StartDefaultTask(void *argument)
{
  /* init code for LWIP */
  MX_LWIP_Init();
  /* USER CODE BEGIN 5 */
  /* Infinite loop */
  for(;;)
  {
    osDelay(100);
  }
  /* USER CODE END 5 */
}

 /* MPU Configuration */

void MPU_Config(void)
{
  MPU_Region_InitTypeDef MPU_InitStruct = {0};

  /* Disables the MPU */
  HAL_MPU_Disable();

  /** Initializes and configures the Region and the memory to be protected
  */
  MPU_InitStruct.Enable = MPU_REGION_ENABLE;
  MPU_InitStruct.Number = MPU_REGION_NUMBER0;
  MPU_InitStruct.BaseAddress = 0x24000000;
  MPU_InitStruct.Size = MPU_REGION_SIZE_512KB;
  MPU_InitStruct.SubRegionDisable = 0x0;
  MPU_InitStruct.TypeExtField = MPU_TEX_LEVEL1;
  MPU_InitStruct.AccessPermission = MPU_REGION_FULL_ACCESS;
  MPU_InitStruct.DisableExec = MPU_INSTRUCTION_ACCESS_DISABLE;
  MPU_InitStruct.IsShareable = MPU_ACCESS_NOT_SHAREABLE;
  MPU_InitStruct.IsCacheable = MPU_ACCESS_CACHEABLE;
  MPU_InitStruct.IsBufferable = MPU_ACCESS_BUFFERABLE;

  HAL_MPU_ConfigRegion(&MPU_InitStruct);

  /** Initializes and configures the Region and the memory to be protected
  */
  MPU_InitStruct.Number = MPU_REGION_NUMBER1;
  MPU_InitStruct.BaseAddress = 0x70000000;
  MPU_InitStruct.Size = MPU_REGION_SIZE_512MB;
  MPU_InitStruct.TypeExtField = MPU_TEX_LEVEL0;
  MPU_InitStruct.AccessPermission = MPU_REGION_NO_ACCESS;
  MPU_InitStruct.IsCacheable = MPU_ACCESS_NOT_CACHEABLE;
  MPU_InitStruct.IsBufferable = MPU_ACCESS_NOT_BUFFERABLE;

  HAL_MPU_ConfigRegion(&MPU_InitStruct);

  /** Initializes and configures the Region and the memory to be protected
  */
  MPU_InitStruct.Number = MPU_REGION_NUMBER2;
  MPU_InitStruct.Size = MPU_REGION_SIZE_8MB;
  MPU_InitStruct.AccessPermission = MPU_REGION_FULL_ACCESS;
  MPU_InitStruct.IsCacheable = MPU_ACCESS_CACHEABLE;
  MPU_InitStruct.IsBufferable = MPU_ACCESS_BUFFERABLE;

  HAL_MPU_ConfigRegion(&MPU_InitStruct);

  /** Initializes and configures the Region and the memory to be protected
  */
  MPU_InitStruct.Number = MPU_REGION_NUMBER3;
  MPU_InitStruct.BaseAddress = 0x90000000;
  MPU_InitStruct.Size = MPU_REGION_SIZE_512MB;
  MPU_InitStruct.AccessPermission = MPU_REGION_NO_ACCESS;
  MPU_InitStruct.IsCacheable = MPU_ACCESS_NOT_CACHEABLE;
  MPU_InitStruct.IsBufferable = MPU_ACCESS_NOT_BUFFERABLE;

  HAL_MPU_ConfigRegion(&MPU_InitStruct);

  /** Initializes and configures the Region and the memory to be protected
  */
  MPU_InitStruct.Number = MPU_REGION_NUMBER4;
  MPU_InitStruct.Size = MPU_REGION_SIZE_64MB;
  MPU_InitStruct.AccessPermission = MPU_REGION_FULL_ACCESS;
  MPU_InitStruct.IsCacheable = MPU_ACCESS_CACHEABLE;

  HAL_MPU_ConfigRegion(&MPU_InitStruct);
  /* Enables the MPU */
  HAL_MPU_Enable(MPU_PRIVILEGED_DEFAULT);

}

void HAL_TIM_PeriodElapsedCallback(TIM_HandleTypeDef *htim)
{
  if (htim->Instance == TIM6)
  {
    HAL_IncTick();
  }
}

void Error_Handler(void)
{
}
